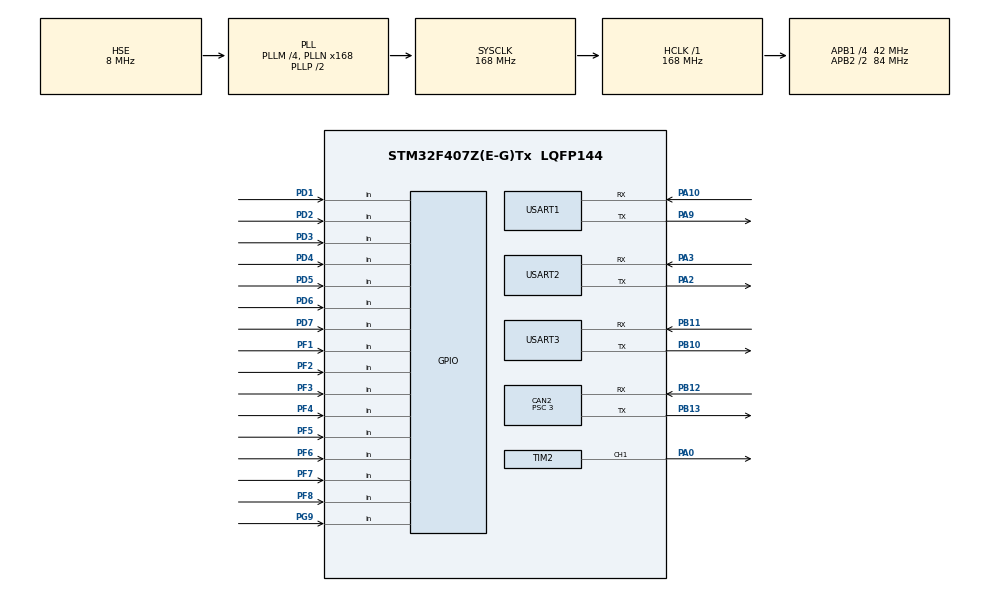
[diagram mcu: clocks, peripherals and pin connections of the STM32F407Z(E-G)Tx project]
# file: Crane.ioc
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CAN2.ABOM=ENABLE
CAN2.BS1=CAN_BS1_9TQ
CAN2.BS2=CAN_BS2_4TQ
CAN2.CalculateBaudRate=1000000
CAN2.CalculateTimeBit=1000
CAN2.CalculateTimeQuantum=71.42857142857143
CAN2.Prescaler=3
Mcu.Family=STM32F4
Mcu.Name=STM32F407Z(E-G)Tx
Mcu.Package=LQFP144
NVIC.CAN2_RX0_IRQn=true\:0\:0\:false\:false\:true\:true\:true\:true
NVIC.PriorityGroup=NVIC_PRIORITYGROUP_4
NVIC.TIM1_UP_TIM10_IRQn=true\:0\:0\:false\:false\:true\:true\:true\:true
NVIC.TIM2_IRQn=true\:0\:0\:false\:false\:true\:true\:true\:true
NVIC.USART1_IRQn=true\:0\:0\:false\:false\:true\:true\:true\:true
NVIC.USART2_IRQn=true\:0\:0\:false\:false\:true\:true\:true\:true
NVIC.USART3_IRQn=true\:0\:0\:false\:false\:true\:true\:true\:true
PA0-WKUP.Signal=S_TIM2_CH1_ETR
PA10.Mode=Asynchronous
PA10.Signal=USART1_RX
PA13.Mode=Serial_Wire
PA13.Signal=SYS_JTMS-SWDIO
PA14.Mode=Serial_Wire
PA14.Signal=SYS_JTCK-SWCLK
PA2.Mode=Asynchronous
PA2.Signal=USART2_TX
PA3.Mode=Asynchronous
PA3.Signal=USART2_RX
PA9.Mode=Asynchronous
PA9.Signal=USART1_TX
PB10.Mode=Asynchronous
PB10.Signal=USART3_TX
PB11.Mode=Asynchronous
PB11.Signal=USART3_RX
PB12.Mode=CAN_Activate
PB12.Signal=CAN2_RX
PB13.Mode=CAN_Activate
PB13.Signal=CAN2_TX
PC14-OSC32_IN.Mode=LSE-External-Oscillator
PC14-OSC32_IN.Signal=RCC_OSC32_IN
PC15-OSC32_OUT.Mode=LSE-External-Oscillator
PC15-OSC32_OUT.Signal=RCC_OSC32_OUT
PD1.Signal=GPIO_Input
PD2.Signal=GPIO_Input
PD3.Signal=GPIO_Input
PD4.Signal=GPIO_Input
PD5.Signal=GPIO_Input
PD6.Signal=GPIO_Input
PD7.Signal=GPIO_Input
PF1.Signal=GPIO_Input
PF2.Signal=GPIO_Input
PF3.Signal=GPIO_Input
PF4.Signal=GPIO_Input
PF5.Signal=GPIO_Input
PF6.Signal=GPIO_Input
PF7.Signal=GPIO_Input
PF8.Signal=GPIO_Input
PG9.Signal=GPIO_Input
PH0-OSC_IN.Mode=HSE-External-Oscillator
PH0-OSC_IN.Signal=RCC_OSC_IN
PH1-OSC_OUT.Mode=HSE-External-Oscillator
PH1-OSC_OUT.Signal=RCC_OSC_OUT
ProjectManager.HeapSize=0x200
ProjectManager.StackSize=0x400
ProjectManager.TargetToolchain=MDK-ARM V5.32
RCC.48MHZClocksFreq_Value=84000000
RCC.AHBFreq_Value=168000000
RCC.APB1CLKDivider=RCC_HCLK_DIV4
RCC.APB1Freq_Value=42000000
RCC.APB1TimFreq_Value=84000000
RCC.APB2CLKDivider=RCC_HCLK_DIV2
RCC.APB2Freq_Value=84000000
RCC.APB2TimFreq_Value=168000000
RCC.CortexFreq_Value=168000000
RCC.HCLKFreq_Value=168000000
RCC.HSE_VALUE=8000000
RCC.HSI_VALUE=16000000
RCC.PLLM=4
RCC.PLLN=168
RCC.PLLSourceVirtual=RCC_PLLSOURCE_HSE
RCC.SYSCLKFreq_VALUE=168000000
RCC.SYSCLKSource=RCC_SYSCLKSOURCE_PLLCLK
RCC.VCOOutputFreq_Value=336000000
SH.S_TIM2_CH1_ETR.0=TIM2_CH1,PWM Generation1 CH1
TIM1.AutoReloadPreload=TIM_AUTORELOAD_PRELOAD_ENABLE
TIM1.Period=9999
TIM1.Prescaler=167
TIM2.Channel-PWM\ Generation1\ CH1=TIM_CHANNEL_1
TIM2.Period=999
TIM2.Prescaler=83
USART1.VirtualMode=VM_ASYNC
USART2.VirtualMode=VM_ASYNC
USART3.VirtualMode=VM_ASYNC
VP_TIM1_VS_ClockSourceINT.Mode=Internal
VP_TIM2_VS_ClockSourceINT.Mode=Internal
board=custom

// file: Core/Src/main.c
/* USER CODE BEGIN Header */
/**
  ******************************************************************************
  * @file           : main.c
  * @brief          : Main program body
  ******************************************************************************
  * @attention
  *
  * Copyright (c) 2024 STMicroelectronics.
  * All rights reserved.
  *
  * This software is licensed under terms that can be found in the LICENSE file
  * in the root directory of this software component.
  * If no LICENSE file comes with this software, it is provided AS-IS.
  *
  ******************************************************************************
  */
/* USER CODE END Header */
#include "main.h"
#include "can.h"
#include "tim.h"
#include "usart.h"
#include "gpio.h"

/* USER CODE BEGIN Includes */
#include "pid.h"
#include "bsp_can.h"
/* USER CODE END Includes */

/* USER CODE BEGIN PD */
// #define readl1 HAL_GPIO_ReadPin(GPIOF,GPIO_PIN_1)
// #define readl2 HAL_GPIO_ReadPin(GPIOF,GPIO_PIN_2)
// #define readl3 HAL_GPIO_ReadPin(GPIOF,GPIO_PIN_3)
// #define readl4 HAL_GPIO_ReadPin(GPIOF,GPIO_PIN_4)
// #define readl5 HAL_GPIO_ReadPin(GPIOF,GPIO_PIN_5)
// #define readl6 HAL_GPIO_ReadPin(GPIOF,GPIO_PIN_6)
// #define readl7 HAL_GPIO_ReadPin(GPIOF,GPIO_PIN_7)
// #define readl8 HAL_GPIO_ReadPin(GPIOF,GPIO_PIN_8)

// #define readl1 HAL_GPIO_ReadPin(GPIOD,GPIO_PIN_1)
// #define readl2 HAL_GPIO_ReadPin(GPIOD,GPIO_PIN_2)
// #define readl3 HAL_GPIO_ReadPin(GPIOD,GPIO_PIN_3)
// #define readl4 HAL_GPIO_ReadPin(GPIOD,GPIO_PIN_4)
// #define readl5 HAL_GPIO_ReadPin(GPIOD,GPIO_PIN_5)
// #define readl6 HAL_GPIO_ReadPin(GPIOD,GPIO_PIN_6)
// #define readl7 HAL_GPIO_ReadPin(GPIOD,GPIO_PIN_7)
// #define readl8 HAL_GPIO_ReadPin(GPIOG,GPIO_PIN_9)
/* USER CODE END PD */

extern uint8_t Send;
extern uint8_t path[10];
extern uint8_t newplace;
extern uint8_t stop;
extern float adjust;//调整速度变量
/* USER CODE BEGIN PV */
// uint8_t poschange=1;
// uint8_t stop=1;
// static int8_t adjust=0;
// tPid stop_control;
/* USER CODE END PV */

void SystemClock_Config(void);
/* USER CODE BEGIN PFP */
// void position_control(void);
void Position_RTx(void);
/* USER CODE END PFP */

int main(void)
{

  /* MCU Configuration--------------------------------------------------------*/

  /* Reset of all peripherals, Initializes the Flash interface and the Systick. */
  HAL_Init();

  /* USER CODE BEGIN Init */
  Classic_init();
  /* USER CODE END Init */

  /* Configure the system clock */
  SystemClock_Config();

  /* Initialize all configured peripherals */
  MX_GPIO_Init();
  MX_CAN2_Init();
  MX_TIM2_Init();
  MX_USART1_UART_Init();
  MX_USART2_UART_Init();
  MX_USART3_UART_Init();
  MX_TIM1_Init();
  /* USER CODE BEGIN 2 */
	HAL_UART_Receive_IT(&huart2, (uint8_t *)&aRxBuffer2, 1);

  // HAL_Delay (1500);
	can_filter_init(&hcan2);
  HAL_TIM_Base_Start_IT(&htim1);
//	for(int i=0; i<4; i++)
//  {
//    pid_init(&motor_pid[i]);
//    motor_pid[i].f_param_init(&motor_pid[i],16384,5000,10,0,5000,0,1.0,0.0005,0);
//  }

  /* USER CODE END 2 */

  /* Infinite loop */
  /* USER CODE BEGIN WHILE */
  while (1)
  {
//		HAL_Delay(50);
		// set_moto_current(500, 500, 500, 500);

    /* USER CODE END WHILE */

    /* USER CODE BEGIN 3 */
    Position_RTx();

  }
  /* USER CODE END 3 */
}

void SystemClock_Config(void)
{
  RCC_OscInitTypeDef RCC_OscInitStruct = {0};
  RCC_ClkInitTypeDef RCC_ClkInitStruct = {0};

  /** Configure the main internal regulator output voltage
  */
  __HAL_RCC_PWR_CLK_ENABLE();
  __HAL_PWR_VOLTAGESCALING_CONFIG(PWR_REGULATOR_VOLTAGE_SCALE1);

  /** Initializes the RCC Oscillators according to the specified parameters
  * in the RCC_OscInitTypeDef structure.
  */
  RCC_OscInitStruct.OscillatorType = RCC_OSCILLATORTYPE_HSE;
  RCC_OscInitStruct.HSEState = RCC_HSE_ON;
  RCC_OscInitStruct.PLL.PLLState = RCC_PLL_ON;
  RCC_OscInitStruct.PLL.PLLSource = RCC_PLLSOURCE_HSE;
  RCC_OscInitStruct.PLL.PLLM = 4;
  RCC_OscInitStruct.PLL.PLLN = 168;
  RCC_OscInitStruct.PLL.PLLP = RCC_PLLP_DIV2;
  RCC_OscInitStruct.PLL.PLLQ = 4;
  if (HAL_RCC_OscConfig(&RCC_OscInitStruct) != HAL_OK)
  {
    Error_Handler();
  }

  /** Initializes the CPU, AHB and APB buses clocks
  */
  RCC_ClkInitStruct.ClockType = RCC_CLOCKTYPE_HCLK|RCC_CLOCKTYPE_SYSCLK
                              |RCC_CLOCKTYPE_PCLK1|RCC_CLOCKTYPE_PCLK2;
  RCC_ClkInitStruct.SYSCLKSource = RCC_SYSCLKSOURCE_PLLCLK;
  RCC_ClkInitStruct.AHBCLKDivider = RCC_SYSCLK_DIV1;
  RCC_ClkInitStruct.APB1CLKDivider = RCC_HCLK_DIV4;
  RCC_ClkInitStruct.APB2CLKDivider = RCC_HCLK_DIV2;

  if (HAL_RCC_ClockConfig(&RCC_ClkInitStruct, FLASH_LATENCY_5) != HAL_OK)
  {
    Error_Handler();
  }
}

/* USER CODE BEGIN 4 */
// void position_control(void)
// {
//   if(readl1==0||readl8==0)
//   {
//     poschange=1;
//     if(stop==1)
//     {
//       if(readl2==0&&readl3==1&&readl4==1&&readl5==1&&readl6==1&&readl7==1)
//       {
//         adjust=-SPEED*0.5f;
//       }
//       else if(readl2==1&&readl3==0&&readl4==1&&readl5==1&&readl6==1&&readl7==1)
//       {
//         adjust=-SPEED*0.7f;
//       }
//       else if(readl2==1&&readl3==1&&readl4==0&&readl5==1&&readl6==1&&readl7==1)
//       {
//         adjust=-SPEED*0.9f;
//       }
//       else if(readl2==1&&readl3==1&&readl4==1&&readl5==0&&readl6==1&&readl7==1)
//       {
//         adjust=-SPEED*1.1f;
//       }
//       else if(readl2==1&&readl3==1&&readl4==1&&readl5==1&&readl6==0&&readl7==1)
//       {
//         adjust=-SPEED*1.3f;
//       }
//       else if(readl2==1&&readl3==1&&readl4==1&&readl5==1&&readl6==1&&readl7==0)
//       {
//         adjust=-SPEED*1.5f;
//       }
//       else if(readl2==1&&readl3==1&&readl4==0&&readl5==0&&readl6==1&&readl7==1)
//       {
//         adjust=-SPEED;
//       }
//       // else
//       // {
//       //   adjust=0.0f;
//       // }
//       if(adjust!=0)
//       {
//         PID_stop_realize(&stop_control,adjust,-SPEED);
//       }
//     }
//   }
//   else
//   {
//     stop_control.out=0.0f;
//   }
// }
void Position_RTx(void)
{
  // if(Send==1)
  // {
  //   HAL_UART_Transmit(&huart2,&path[newplace],sizeof(&path[newplace]),10000);
  //   Send=0;
  // }
  if(stop==1)
  {
    HAL_Delay(20000);
    stop=0;
    adjust=0.0f;
  }
}
/* USER CODE END 4 */

void Error_Handler(void)
{
  __disable_irq();
  while (1)
  {
  }
}
